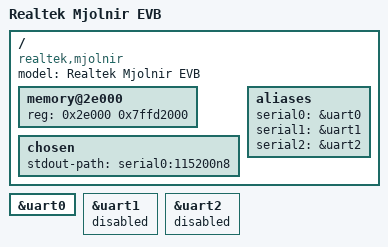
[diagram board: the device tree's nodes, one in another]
// SPDX-License-Identifier: (GPL-2.0-or-later OR BSD-2-Clause)
/*
 * Copyright (c) 2019 Realtek Semiconductor Corp.
 * Copyright (c) 2019 Andreas Färber
 */

/dts-v1/;

#include "rtd1619.dtsi"

/ {
	compatible = "realtek,mjolnir", "realtek,rtd1619";
	model = "Realtek Mjolnir EVB";

	memory@2e000 {
		device_type = "memory";
		reg = <0x2e000 0x7ffd2000>; /* boot ROM to 2 GiB */
	};

	chosen {
		stdout-path = "serial0:115200n8";
	};

	aliases {
		serial0 = &uart0;
		serial1 = &uart1;
		serial2 = &uart2;
	};
};

/* debug console (J1) */
&uart0 {
	status = "okay";
};

/* M.2 slot (CON4) */
&uart1 {
	status = "disabled";
};

/* GPIO connector (T1) */
&uart2 {
	status = "disabled";
};
